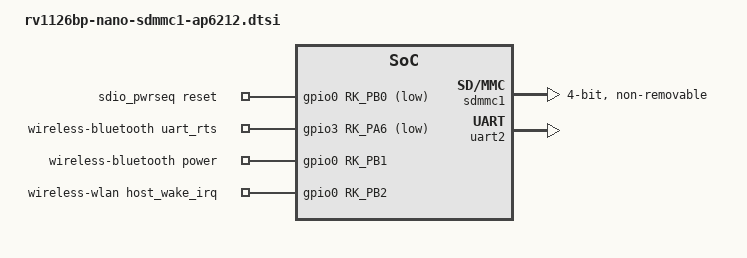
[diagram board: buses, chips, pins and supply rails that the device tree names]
// SPDX-License-Identifier: (GPL-2.0+ OR MIT)
/*
 * Copyright (c) 2025 Guangzhou EASY EAI Technology Co., Ltd.
 */

/ {
	sdio_pwrseq: sdio-pwrseq {
		compatible = "mmc-pwrseq-simple";
		pinctrl-names = "default";
		pinctrl-0 = <&wifi_enable_h>;

		/*
		 * On the module itself this is one of these (depending
		 * on the actual card populated):
		 * - SDIO_RESET_L_WL_REG_ON
		 * - PDN (power down when low)
		 */
		reset-gpios = <&gpio0 RK_PB0 GPIO_ACTIVE_LOW>;
	};

	wireless-bluetooth {
		compatible = "bluetooth-platdata";
		uart_rts_gpios = <&gpio3 RK_PA6 GPIO_ACTIVE_LOW>;
		pinctrl-names = "default", "rts_gpio";
		pinctrl-0 = <&uart2m0_rtsn_pins>;
		pinctrl-1 = <&uart2_gpios>;
		BT,power_gpio = <&gpio0 RK_PB1 GPIO_ACTIVE_HIGH>;
		status = "okay";
	};

	wireless-wlan {
		compatible = "wlan-platdata";
		rockchip,grf = <&grf>;
		pinctrl-names = "default";
		pinctrl-0 = <&wifi_wake_host>;
		wifi_chip_type = "rk96x";
		WIFI,host_wake_irq = <&gpio0 RK_PB2 GPIO_ACTIVE_HIGH>;
		status = "okay";
	};
};

&pinctrl {
	sdio-pwrseq {
		wifi_enable_h: wifi-enable-h {
			rockchip,pins = <0 RK_PB0 RK_FUNC_GPIO &pcfg_pull_none>;
		};
	};

	wireless-bluetooth {
		uart2_gpios: uart2-gpios {
			rockchip,pins = <3 RK_PA6 RK_FUNC_GPIO &pcfg_pull_none>;
		};
	};

	wireless-wlan {
		wifi_wake_host: wifi-wake-host {
			rockchip,pins = <0 RK_PB2 RK_FUNC_GPIO &pcfg_pull_up>;
		};
	};
};

&sdmmc1 {
	bus-width = <4>;
	cap-sd-highspeed;
	no-sd;
	no-mmc;
	max-frequency = <200000000>;
	pinctrl-names = "default";
	pinctrl-0 = <&sdmmc1_clk_pins &sdmmc1_cmd_pins &sdmmc1_bus4_pins>;
	keep-power-in-suspend;
	non-removable;
	mmc-pwrseq = <&sdio_pwrseq>;
	sd-uhs-sdr104;
	status = "okay";
};

&uart2 {
	status = "okay";
	pinctrl-names = "default";
	pinctrl-0 = <&uart2m0_xfer_pins &uart2m0_ctsn_pins>;
};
